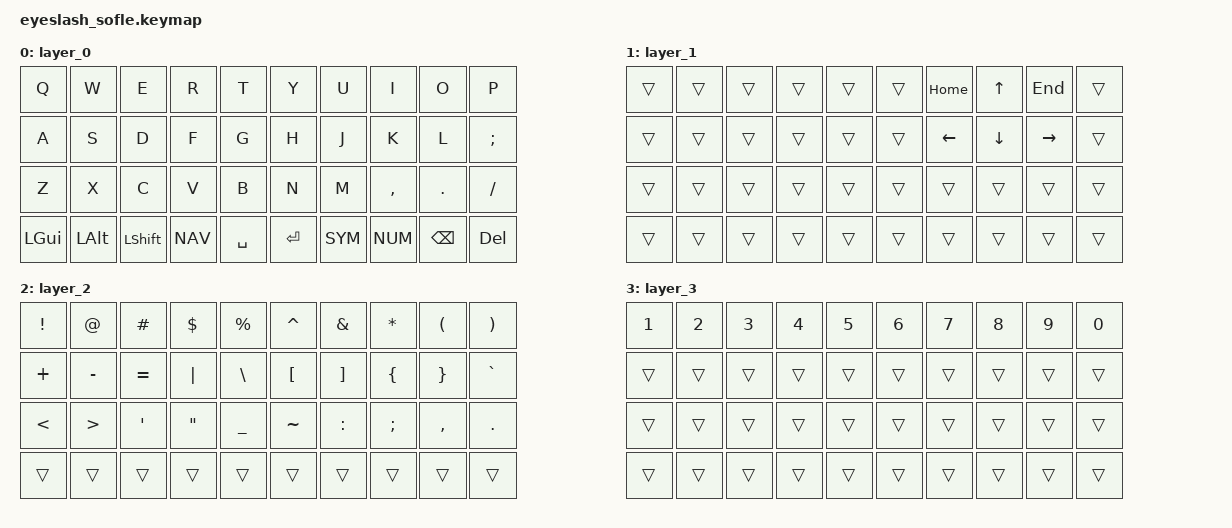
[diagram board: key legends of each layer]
// ----------------------------
// SOFLE OLED – KEYMAP ADRIÁN
// ----------------------------

#include <behaviors.dtsi>
#include <dt-bindings/zmk/keys.h>
#include <dt-bindings/zmk/bt.h>
#include <dt-bindings/zmk/outputs.h>

#define NAV MO(1)
#define SYM MO(2)
#define NUM MO(3)

#define ES_NT  LC(LS(N))   // Ñ mayúscula
#define ES_nn  RA(N)       // ñ minúscula

/ {
    keymap {
        compatible = "zmk,keymap";

        // ----------------------------
        // LAYER 0 – BASE (ES)
        // ----------------------------
        layer_0 {
            bindings = <
                &kp Q      &kp W      &kp E      &kp R      &kp T          &kp Y      &kp U      &kp I      &kp O      &kp P
                &kp A      &kp S      &kp D      &kp F      &kp G          &kp H      &kp J      &kp K      &kp L      &kp SEMI
                &kp Z      &kp X      &kp C      &kp V      &kp B          &kp N      &kp M      &kp COMMA  &kp DOT    &kp SLASH

                &kp LGUI   &kp LALT   &kp LSHIFT NAV        &kp SPACE      &kp ENTER  SYM        NUM        &kp BSPC   &kp DEL
            >;
        };

        // ----------------------------
        // LAYER 1 – NAV (FLECHAS)
        // ----------------------------
        layer_1 {
            bindings = <
                &trans     &trans     &trans     &trans     &trans         &trans     &kp HOME   &kp UP     &kp END    &trans
                &trans     &trans     &trans     &trans     &trans         &trans     &kp LEFT   &kp DOWN   &kp RIGHT  &trans
                &trans     &trans     &trans     &trans     &trans         &trans     &trans     &trans     &trans     &trans

                &trans     &trans     &trans     &trans     &trans         &trans     &trans     &trans     &trans     &trans
            >;
        };

        // ----------------------------
        // LAYER 2 – SÍMBOLOS
        // ----------------------------
        layer_2 {
            bindings = <
                &kp EXCL   &kp AT     &kp HASH   &kp DLLR   &kp PERCENT    &kp CARET  &kp AMPS   &kp STAR   &kp LPAR   &kp RPAR
                &kp PLUS   &kp MINUS  &kp EQUAL  &kp PIPE   &kp BSLH       &kp LBKT   &kp RBKT   &kp LBRC   &kp RBRC   &kp GRAVE
                &kp LT     &kp GT     &kp SQT    &kp DQT    &kp UNDER      &kp TILDE  &kp COLON  &kp SEMI   &kp COMMA  &kp DOT

                &trans     &trans     &trans     &trans     &trans         &trans     &trans     &trans     &trans     &trans
            >;
        };

        // ----------------------------
        // LAYER 3 – NÚMEROS
        // ----------------------------
        layer_3 {
            bindings = <
                &kp N1     &kp N2     &kp N3     &kp N4     &kp N5         &kp N6     &kp N7     &kp N8     &kp N9     &kp N0
                &trans     &trans     &trans     &trans     &trans         &trans     &trans     &trans     &trans     &trans
                &trans     &trans     &trans     &trans     &trans         &trans     &trans     &trans     &trans     &trans

                &trans     &trans     &trans     &trans     &trans         &trans     &trans     &trans     &trans     &trans
            >;
        };
    };
};


